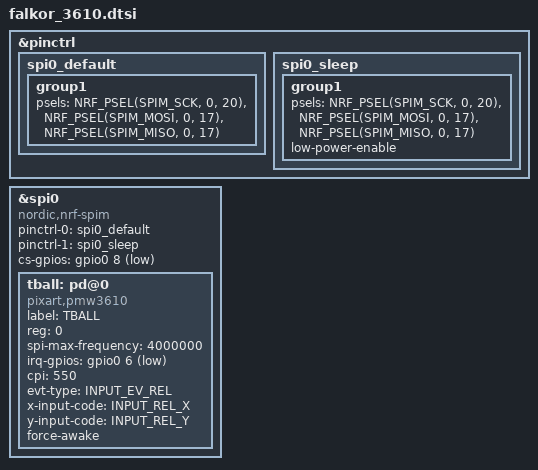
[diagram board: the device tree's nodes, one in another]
&pinctrl {
    spi0_default: spi0_default {
        group1 {
            psels = <NRF_PSEL(SPIM_SCK, 0, 20)>,
                <NRF_PSEL(SPIM_MOSI, 0, 17)>,
                <NRF_PSEL(SPIM_MISO, 0, 17)>;
        };
    };

    spi0_sleep: spi0_sleep {
        group1 {
            psels = <NRF_PSEL(SPIM_SCK, 0, 20)>,
                <NRF_PSEL(SPIM_MOSI, 0, 17)>,
                <NRF_PSEL(SPIM_MISO, 0, 17)>;
            low-power-enable;
        };
    };
};

&spi0 {
	compatible = "nordic,nrf-spim";
	status = "disabled"; // <<< disabled in main .dtsi, okay in .overlay
	tball: pd@0 {
		compatible = "pixart,pmw3610";
		status = "disabled";
		label = "TBALL";
		reg = <0>;
		spi-max-frequency = <4000000>;
	};
};

// Config custom gpios
&spi0 {
  status = "okay";
	pinctrl-0 = <&spi0_default>;
	pinctrl-1 = <&spi0_sleep>;
	pinctrl-names = "default", "sleep";
	cs-gpios = <&gpio0 8 GPIO_ACTIVE_LOW>;
};

#include <zephyr/dt-bindings/input/input-event-codes.h>

&tball {
  status = "okay";
	irq-gpios = <&gpio0 6 (GPIO_ACTIVE_LOW | GPIO_PULL_UP)>;
	cpi = <550>;
	evt-type = <INPUT_EV_REL>;
	x-input-code = <INPUT_REL_X>;
	y-input-code = <INPUT_REL_Y>;
	force-awake;
};
